# PT32x066xx register map
File version: 0.3
Registers are 32-bit, read-write, reset 0x0 unless marked. A register's access mark holds for its fields unless they carry their own. Offsets are from the block's base; [hi:lo] are bit positions; {n}, {i} and the like mark numbered series.

## LPUART0 — Lowpower Universal Asynchronous Receiver Transmitter
Base 0x40004000
Same registers: LPUART1 0x40004C00
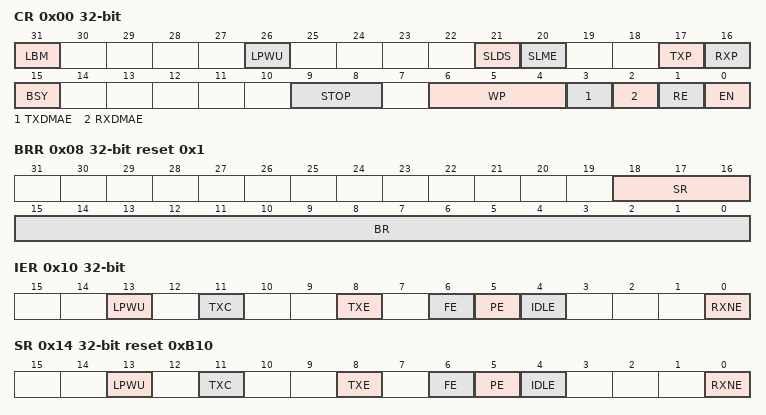
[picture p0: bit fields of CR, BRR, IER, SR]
0x00 CR — Control Register
  [31] LBM — loopback mode
  [26] LPWU — Low power mode wakeup method
  [21] SLDS — Single-line direction setting
  [20] SLME — Single-line mode enable
  [17] TXP — Transmitter polarity control
  [16] RXP — Receiver polarity control
  [15] BSY — Register busy
  [9:8] STOP — Stop bit length
  [6:4] WP — Word length and parity config
  [3] TXDMAE — Tx DMA request enable
  [2] RXDMAE — Rx DMA request enable
  [1] RE — Receive enable
  [0] EN — UART enable
0x08 BRR reset 0x1 — Baud Rate Register
  [18:16] SR — Sample rate
  [15:0] BR — Baud rate control
0x10 IER — Interrupt Enable Register
  [13] LPWU — Low power wakeup interrupt enable
  [11] TXC — Transmit complete interrupt enable
  [8] TXE — Transmit FIFO empty interrupt enable
  [6] FE — frame error interrupt enable
  [5] PE — parity error interrupt enable
  [4] IDLE — Idle timeout interrupt enable
  [0] RXNE — Receive/Receive-FIFO not empty interrupt enable
0x14 SR reset 0xB10 — Status Register
  [13] LPWU ro — Low power wakeup flag
  [11] TXC ro — Transmit complete flag
  [8] TXE ro — Transmit/Transmit-FIFO empty flag
  [6] FE — Frame error flag
  [5] PE — Parity error flag
  [4] IDLE — Idle overtime interrupt enable
  [0] RXNE — Receive/Receive-FIFO not empty flag
0x18 DR — Data Register
  [8:0] DR — UART data

## OPA0 — Operational Amplifier
Base 0x40015C00
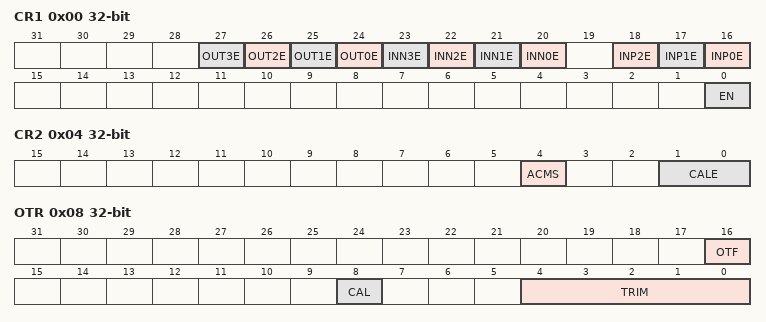
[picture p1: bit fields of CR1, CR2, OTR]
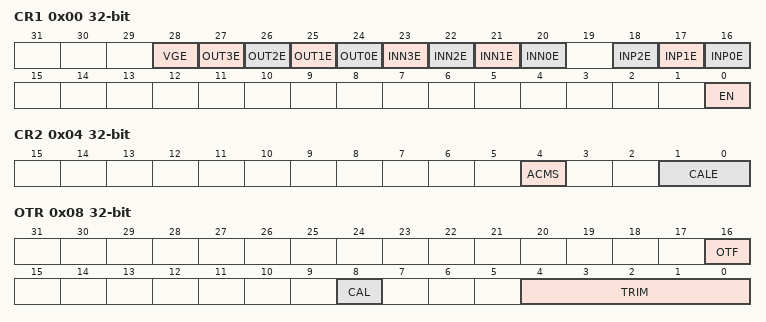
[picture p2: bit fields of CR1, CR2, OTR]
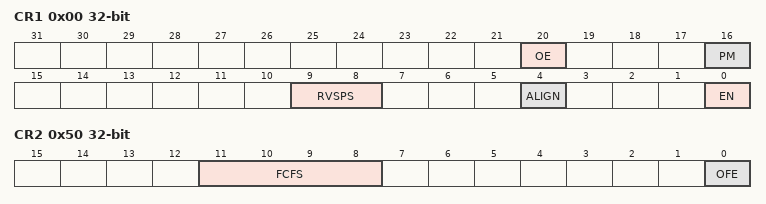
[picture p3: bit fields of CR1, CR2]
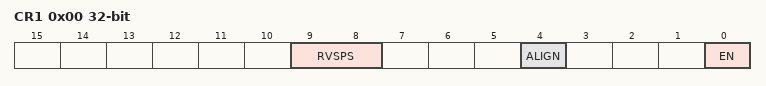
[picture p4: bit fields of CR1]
0x00 CR1 — Control Register 1
  [n+24] OUT{n}E (n=0..3) — OPA output {n} enable
  [n+20] INN{n}E (n=0..3) — OPA negative intput {n} enable
  [18] INP2E — OPA positive intput 2 enable
  [17] INP1E — OPA positive intput 1 enable
  [16] INP0E — OPA positive intput 0 enable
  [0] EN — OPA enable
0x04 CR2 — Control Register 2
  [4] ACMS — Automatic calibration mode selection
  [1:0] CALE — Calibration mode enable
0x08 OTR access per field — Offset Trimming Register
  [16] OTF ro — Offset trimming value source flag
  [8] CAL ro — OPA calibration output
  [4:0] TRIM rw — Offset trimming value

## OPA1 — Operational Amplifier
Base 0x40015D00
0x00 CR1 — Control Register 1
  [28] VGE — OPA virtual ground enable
  [n+24] OUT{n}E (n=0..3) — OPA output {n} enable
  [n+20] INN{n}E (n=0..3) — OPA negative intput {n} enable
  [18] INP2E — OPA positive intput 2 enable
  [17] INP1E — OPA positive intput 1 enable
  [16] INP0E — OPA positive intput 0 enable
  [0] EN — OPA enable
0x04 CR2 — Control Register 2
  [4] ACMS — Automatic calibration mode selection
  [1:0] CALE — Calibration mode enable
0x08 OTR access per field — Offset Trimming Register
  [16] OTF ro — Offset trimming value source flag
  [8] CAL ro — OPA calibration output
  [4:0] TRIM rw — Offset trimming value

## DAC0 — Digital-to-Analog Converter
Base 0x40011800
0x00 CR1 — Control Register 1
  [20] OE — DAC output enable
  [16] PM — DAC power mode
  [9:8] RVSPS — DAC reference voltage source positive selection
  [4] ALIGN — DAC data align
  [0] EN — DAC enable
0x04 DR — Data Register
  [15:0] DATA — LDAC data
0x50 CR2 — Control Register 2
  [11:8] FCFS — MFB filter cutoff frequency selection
  [0] OFE — DAC output MFB filter enable

## DAC1 — Digital-to-Analog Converter
Base 0x40011C00
0x00 CR1 — Control Register 1
  [9:8] RVSPS — DAC reference voltage source positive selection
  [4] ALIGN — DAC data align
  [0] EN — DAC enable
0x04 DR — Data Register
  [15:0] DATA — LDAC data

## IFMC — On-chip flash memory controller
Base 0x40000000
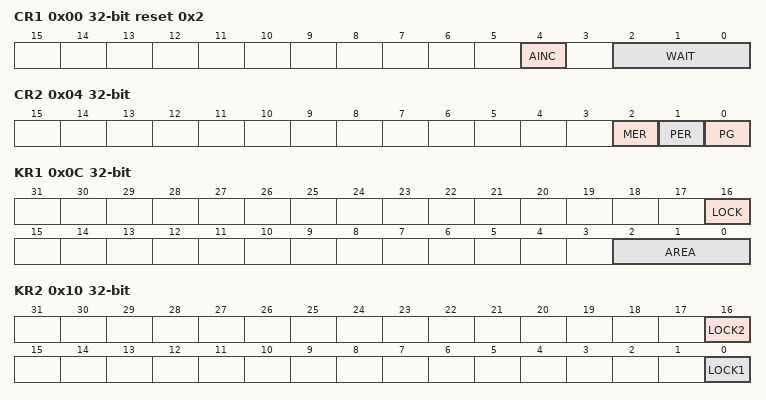
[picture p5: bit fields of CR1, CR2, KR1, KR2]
0x00 CR1 reset 0x2 — Control Register 1
  [4] AINC — Address auto increment control
  [2:0] WAIT — instruction fetch wait cycle
0x04 CR2 wo — Control Register 2
  [2] MER — Mass erase
  [1] PER — Pageerase
  [0] PG — Programming
0x08 PSCR reset 0x40 — Prescaler Register
  [7:0] PSC — Prescaler value
0x0C KR1 ro — Key Register 1
  [16] LOCK — Register lock status
  [2:0] AREA — IFMC operation area
0x10 KR2 ro — Key Register 2
  [16] LOCK2 — Register lock status 2
  [0] LOCK1 — Register lock status 1
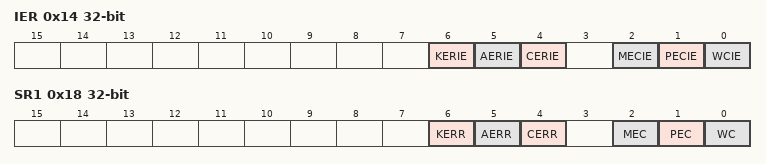
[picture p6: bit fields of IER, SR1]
0x14 IER — Interrupt Enable Register
  [6] KERIE — Key error interrupt enable
  [5] AERIE — Address error interrupt enable
  [4] CERIE — Operation command error interrupt enable
  [2] MECIE — Mass erase operation complete interrupt enable
  [1] PECIE — Page erase operation complete interrupt enable
  [0] WCIE — Write operation complete interrupt enable
0x18 SR1 — Status Register 1
  [6] KERR — Key error
  [5] AERR — Address error
  [4] CERR — Operation command error
  [2] MEC — Mass erase operation complete
  [1] PEC — Page erase operation complete
  [0] WC — Write operation complete
0x20 AR reset 0xFFFFFFFF — Address Register
  [31:0] AR — IFMC words addr
0x24 DR1 — Data Register 1
  [31:0] DR — IFMC data
0x30 OPTCR reset 0xAA — Option Control Register
  [7:0] RDP — Read protect
